# AST1080 register map
File version: 1.0
CPU: CM4 r0p1, little endian, MPU, FPU, 4 interrupt priority bits, 256 interrupts
Registers are 32-bit, read-write, reset 0x0 unless marked. A register's access mark holds for its fields unless they carry their own. Offsets are from the block's base; [hi:lo] are bit positions; {n}, {i} and the like mark numbered series.

## ipc
Base 0x74C39000
Same registers: ipc1 0x74C39100, ipc2 0x74C39200, ipc3 0x74C39300, ipc4 0x74C39400, ipc5 0x74C39500
0x00 IPC000 — IPI trig , w1 trigger
  [3:0] REGIPITRIG
0x04 IPC004 — IPI enable
  [3:0] REGIPIENABLE
0x08 IPC008 — ipi status
  [3:0] REGIPISTATUS
0x0C IPC00C reset not defined — reserved
0x10 IPC010 — tx ipi0 reg0
  [31:0] REGTXIPI00
0x14 IPC014 — tx ipi0 reg1
  [31:0] REGTXIPI01
0x18 IPC018 — tx ipi0 reg2
  [31:0] REGTXIPI02
0x1C IPC01C — tx ipi0 reg3
  [31:0] REGTXIPI03
0x20 IPC020 — tx ipi0 reg4
  [31:0] REGTXIPI04
0x24 IPC024 — tx ipi0 reg5
  [31:0] REGTXIPI05
0x28 IPC028 — tx ipi0 reg6
  [31:0] REGTXIPI06
0x2C IPC02C — tx ipi0 reg7
  [31:0] REGTXIPI07
0x30 IPC030 — tx ipi1 reg0
  [31:0] REGTXIPI10
0x34 IPC034 — tx ipi1 reg1
  [31:0] REGTXIPI11
0x38 IPC038 — tx ipi1 reg2
  [31:0] REGTXIPI12
0x3C IPC03C — tx ipi1 reg3
  [31:0] REGTXIPI13
0x40 IPC040 — tx ipi1 reg4
  [31:0] REGTXIPI14
0x44 IPC044 — tx ipi1 reg5
  [31:0] REGTXIPI15
0x48 IPC048 — tx ipi1 reg6
  [31:0] REGTXIPI16
0x4C IPC04C — tx ipi1 reg7
  [31:0] REGTXIPI17
0x50 IPC050 — tx ipi2 reg0
  [31:0] REGTXIPI20
0x54 IPC054 — tx ipi2 reg1
  [31:0] REGTXIPI21
0x58 IPC058 — tx ipi2 reg2
  [31:0] REGTXIPI22
0x5C IPC05C — tx ipi2 reg3
  [31:0] REGTXIPI23
0x60 IPC060 — tx ipi2 reg4
  [31:0] REGTXIPI24
0x64 IPC064 — tx ipi2 reg5
  [31:0] REGTXIPI25
0x68 IPC068 — tx ipi2 reg6
  [31:0] REGTXIPI26
0x6C IPC06C — tx ipi2 reg7
  [31:0] REGTXIPI27
0x70 IPC070 — tx ipi3 reg0
  [31:0] REGTXIPI30
0x74 IPC074 — tx ipi3 reg1
  [31:0] REGTXIPI31
0x78 IPC078 — tx ipi3 reg2
  [31:0] REGTXIPI32
0x7C IPC07C — tx ipi3 reg3
  [31:0] REGTXIPI33
0x80 IPC080 — tx ipi3 reg4
  [31:0] REGTXIPI34
0x84 IPC084 — tx ipi3 reg5
  [31:0] REGTXIPI35
0x88 IPC088 — tx ipi3 reg6
  [31:0] REGTXIPI36
0x8C IPC08C — tx ipi3 reg7
  [31:0] REGTXIPI37

## rtc
Base 0x74C34000
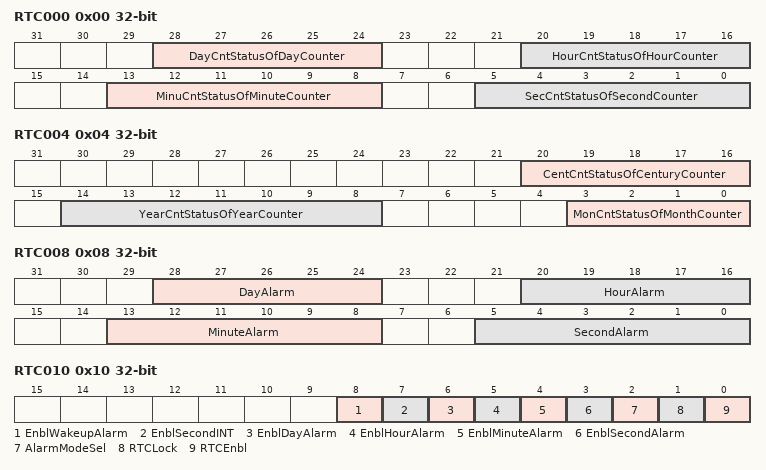
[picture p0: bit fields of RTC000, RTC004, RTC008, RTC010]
0x00 RTC000 — Counter Status Register \#1
  [28:24] DayCntStatusOfDayCounter, [20:16] HourCntStatusOfHourCounter, [13:8] MinuCntStatusOfMinuteCounter, [5:0] SecCntStatusOfSecondCounter
0x04 RTC004 — Counter Status Register \#2
  [20:16] CentCntStatusOfCenturyCounter, [14:8] YearCntStatusOfYearCounter, [3:0] MonCntStatusOfMonthCounter
0x08 RTC008 — Clock Alarm Register
  [28:24] DayAlarm, [20:16] HourAlarm, [13:8] MinuteAlarm, [5:0] SecondAlarm
0x10 RTC010 — Control Register
  [8] EnblWakeupAlarm — Enable wakeup alarm
    1=Enable; 0=Disable
  [7] EnblSecondINT — Enable second interrupt
    1=Enable; 0=Disable
  [6] EnblDayAlarm — Enable day alarm
    1=Enable; 0=Disable
  [5] EnblHourAlarm — Enable hour alarm
    1=Enable; 0=Disable
  [4] EnblMinuteAlarm — Enable minute alarm
    1=Enable; 0=Disable
  [3] EnblSecondAlarm — Enable second alarm
    1=Enable; 0=Disable
  [2] AlarmModeSel — Alarm mode selection
    1=Combination_Mode_Alarm_Is_Issued_When_All_Enabled_Alarm_Were_Met; 0=Individual_Mode_Alarm_Is_Issued_Depending_On_Which_Alarm_Was_Set
  [1] RTCLock
    1=Enable_Update; 0=Disable_Update
  [0] RTCEnbl — RTC enable
    1=Enable; 0=Disable
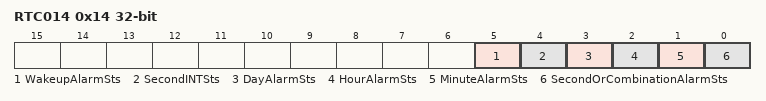
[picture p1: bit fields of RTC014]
0x14 RTC014 — Alarm Status Register
  [all] fields
    1=Alarmed; 0=Idle
  [5] WakeupAlarmSts — Wakeup alarm status
  [4] SecondINTSts — Second interrupt status
  [3] DayAlarmSts — Day alarm status
  [2] HourAlarmSts — Hour alarm status
  [1] MinuteAlarmSts — Minute alarm status
  [0] SecondOrCombinationAlarmSts — Second or Combination alarm status

## at
Base 0x74C35000
0x04 AT004 — Anti-Tamper Interrupt Status
  [31:0] ATINTSTS ro
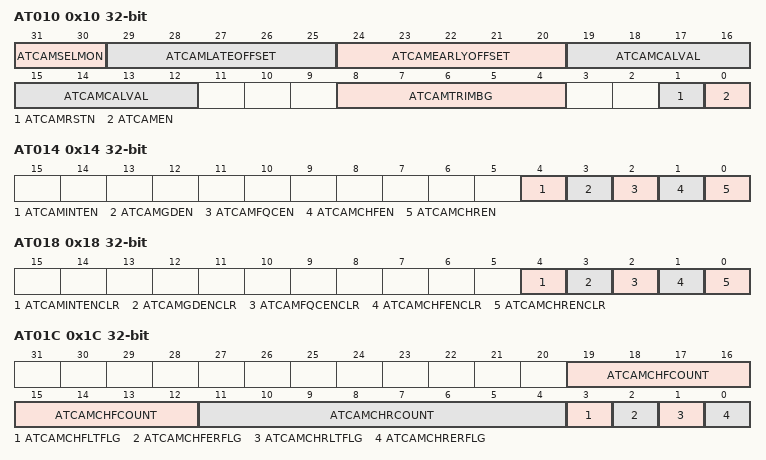
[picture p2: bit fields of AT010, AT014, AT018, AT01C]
0x10 AT010 — Clock Attack Monitor Control
  [31:30] ATCAMSELMON, [29:25] ATCAMLATEOFFSET, [24:20] ATCAMEARLYOFFSET, [19:12] ATCAMCALVAL, [8:4] ATCAMTRIMBG, [1] ATCAMRSTN, [0] ATCAMEN
0x14 AT014 — Clock Attack Monitor Enable Set
  [4] ATCAMINTEN, [3] ATCAMGDEN, [2] ATCAMFQCEN, [1] ATCAMCHFEN, [0] ATCAMCHREN
0x18 AT018 — Clock Attack Monitor Enable Clear
  [4] ATCAMINTENCLR, [3] ATCAMGDENCLR, [2] ATCAMFQCENCLR, [1] ATCAMCHFENCLR, [0] ATCAMCHRENCLR
0x1C AT01C — Clock Attack Monitor Status 0
  [19:12] ATCAMCHFCOUNT ro, [11:4] ATCAMCHRCOUNT ro, [3] ATCAMCHFLTFLG ro, [2] ATCAMCHFERFLG ro, [1] ATCAMCHRLTFLG ro, [0] ATCAMCHRERFLG ro
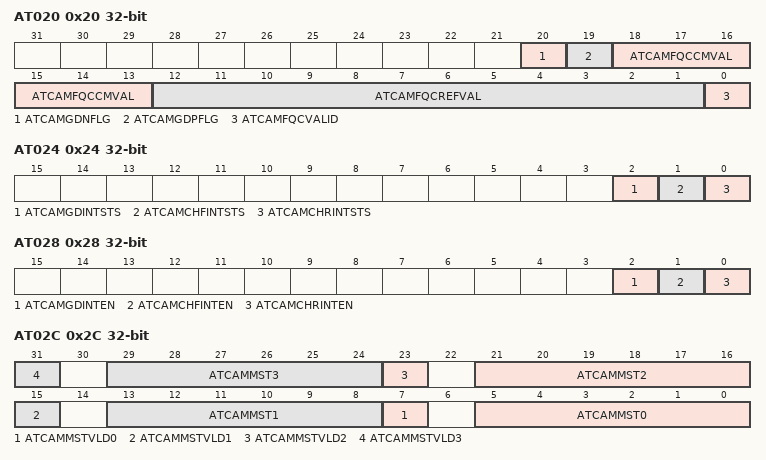
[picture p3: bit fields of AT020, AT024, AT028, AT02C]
0x20 AT020 — Clock Attack Monitor Status 1
  [20] ATCAMGDNFLG ro, [19] ATCAMGDPFLG ro, [18:13] ATCAMFQCCMVAL ro, [12:1] ATCAMFQCREFVAL ro, [0] ATCAMFQCVALID ro
0x24 AT024 — Clock Attack Monitor Interrupt Status
  [2] ATCAMGDINTSTS, [1] ATCAMCHFINTSTS, [0] ATCAMCHRINTSTS
0x28 AT028 — Clock Attack Monitor Interrupt Enable
  [2] ATCAMGDINTEN, [1] ATCAMCHFINTEN, [0] ATCAMCHRINTEN
0x2C AT02C — Clock Attack Monitor Master
  [8n+7] ATCAMMSTVLD{n} (n=0..3), [8n+5:8n] ATCAMMST{n} (n=0..3)
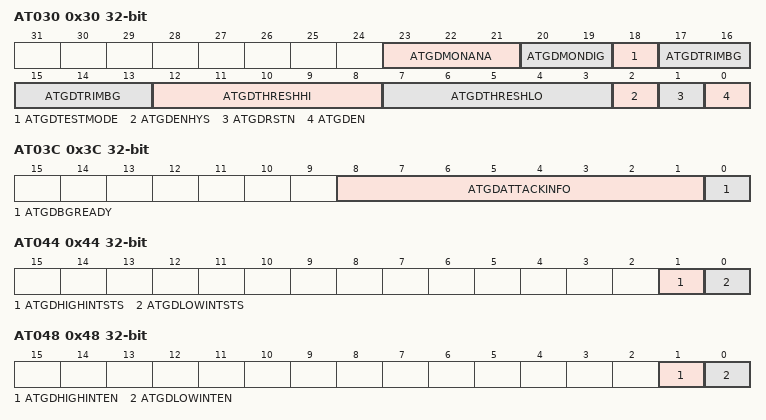
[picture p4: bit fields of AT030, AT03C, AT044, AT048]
0x30 AT030 — Glitch Detection Control
  [23:21] ATGDMONANA, [20:19] ATGDMONDIG, [18] ATGDTESTMODE, [17:13] ATGDTRIMBG, [12:8] ATGDTHRESHHI, [7:3] ATGDTHRESHLO, [2] ATGDENHYS, [1] ATGDRSTN, [0] ATGDEN
0x3C AT03C — Glitch Detection Status
  [8:1] ATGDATTACKINFO ro, [0] ATGDBGREADY ro
0x44 AT044 — Glitch Detection Interrupt Status
  [1] ATGDHIGHINTSTS, [0] ATGDLOWINTSTS
0x48 AT048 — Glitch Detection Interrupt Enable
  [1] ATGDHIGHINTEN, [0] ATGDLOWINTEN
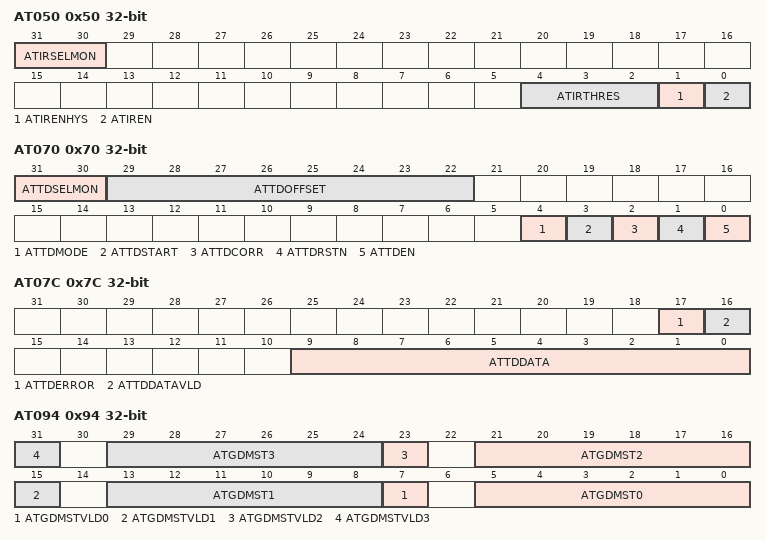
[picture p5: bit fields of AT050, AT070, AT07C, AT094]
0x50 AT050 — IR Drop Control
  [31:30] ATIRSELMON, [4:2] ATIRTHRES, [1] ATIRENHYS, [0] ATIREN
0x64 AT064 — IR Drop Interrupt Status
  [0] ATIRINTSTS
0x68 AT068 — IR Drop Interrupt Enable
  [0] ATIRINTEN
0x70 AT070 — TSENSE Control
  [31:30] ATTDSELMON, [29:22] ATTDOFFSET, [4] ATTDMODE, [3] ATTDSTART, [2] ATTDCORR, [1] ATTDRSTN, [0] ATTDEN
0x74 AT074 reset 0x1 — TSENSE Clock Divisor
  [3:0] ATTDCLKDIV
0x7C AT07C — TSENSE Status
  [17] ATTDERROR ro, [16] ATTDDATAVLD, [9:0] ATTDDATA ro
0x84 AT084 — TSENSE Interrupt Status
  [0] ATTDINTSTS
0x88 AT088 — TSENSE Interrupt Enable
  [0] ATTDINTEN
0x94 AT094 — Glitch Detection Master
  [8n+7] ATGDMSTVLD{n} (n=0..3), [8n+5:8n] ATGDMST{n} (n=0..3)
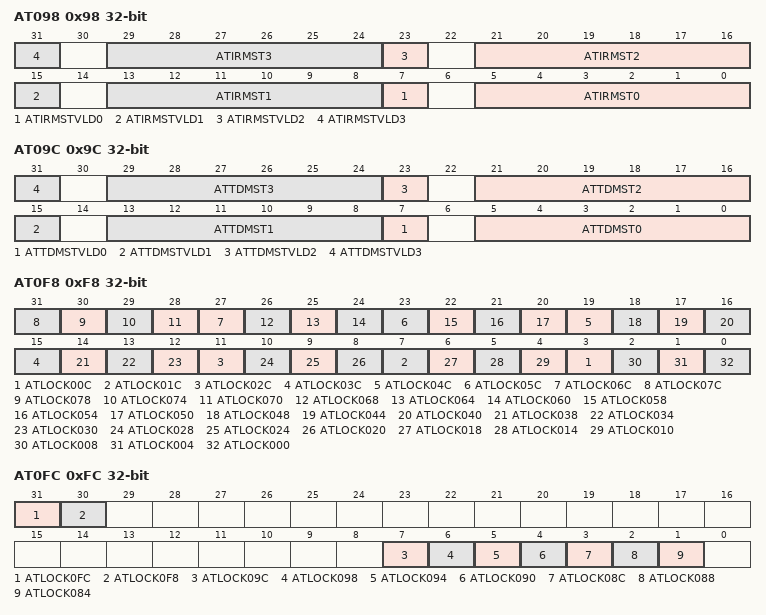
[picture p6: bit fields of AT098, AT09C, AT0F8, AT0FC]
0x98 AT098 — IR Drop Master
  [8n+7] ATIRMSTVLD{n} (n=0..3), [8n+5:8n] ATIRMST{n} (n=0..3)
0x9C AT09C — TSENSE Master
  [8n+7] ATTDMSTVLD{n} (n=0..3), [8n+5:8n] ATTDMST{n} (n=0..3)
0xF8 AT0F8 — Write Protection 1
  [4n+3] ATLOCK{n:02}C (n=0..7), [30] ATLOCK078, [29] ATLOCK074, [28] ATLOCK070, [26] ATLOCK068, [25] ATLOCK064, [24] ATLOCK060, [22] ATLOCK058, [21] ATLOCK054, [20] ATLOCK050, [18] ATLOCK048, [17] ATLOCK044, [16] ATLOCK040, [14] ATLOCK038, [13] ATLOCK034, [12] ATLOCK030, [10] ATLOCK028, [9] ATLOCK024, [8] ATLOCK020, [6] ATLOCK018, [5] ATLOCK014, [4] ATLOCK010, [2] ATLOCK008, [1] ATLOCK004, [0] ATLOCK000
0xFC AT0FC — Write Protection 2
  [31] ATLOCK0FC, [30] ATLOCK0F8, [7] ATLOCK09C, [6] ATLOCK098, [5] ATLOCK094, [4] ATLOCK090, [3] ATLOCK08C, [2] ATLOCK088, [1] ATLOCK084
